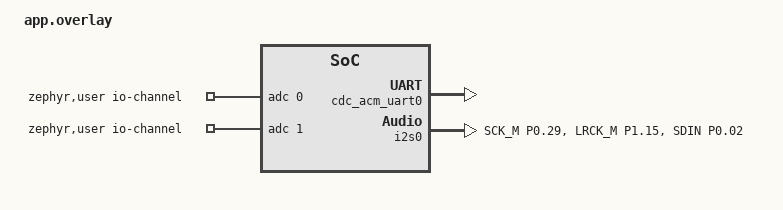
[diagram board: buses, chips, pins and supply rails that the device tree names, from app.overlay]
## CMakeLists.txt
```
# SPDX-License-Identifier: Apache-2.0

cmake_minimum_required(VERSION 3.20.0)
set(QEMU_EXTRA_FLAGS -s)
set(CMAKE_EXPORT_COMPILE_COMMANDS ON)
find_package(Zephyr REQUIRED HINTS $ENV{ZEPHYR_BASE})
project(console)
set(CMAKE_EXPORT_COMPILE_COMMANDS ON)
set(CMAKE_COLOR_DIAGNOSTICS ON)
set(CMAKE_C_FLAGS "${CMAKE_C_FLAGS} -Wall -Wextra -Wformat -Wformat-security -Wshadow -Wwrite-strings -Wcast-qual -Wswitch-default -Wswitch-enum -Wconversion -Wunreachable-code -Wstrict-prototypes")

target_sources(app PRIVATE 
    src/main.c
    src/provision.c
    src/uart.c
    src/board.c
    src/heartbeat.c
    src/msgdata.c
    src/microphone.c
    src/datastructures.c)

target_include_directories(app PRIVATE ${CMAKE_CURRENT_SOURCE_DIR}/includes)
```

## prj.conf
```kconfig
CONFIG_USB_DEVICE_STACK=y
CONFIG_USB_DEVICE_PRODUCT="Mesh DK 1 USB"

CONFIG_SERIAL=y
CONFIG_CONSOLE=y
CONFIG_UART_CONSOLE=n
CONFIG_UART_LINE_CTRL=y
#CONFIG_DK_LIBRARY=y

CONFIG_POSIX_API=y

# Bluetooth configuration
CONFIG_BT=y
CONFIG_BT_COMPANY_ID=0x0059
CONFIG_BT_DEVICE_NAME="Mesh DK 1"
CONFIG_BT_L2CAP_TX_BUF_COUNT=32
CONFIG_BT_OBSERVER=y
CONFIG_BT_PERIPHERAL=y
CONFIG_BT_SETTINGS=y

CONFIG_BT_CTLR_PHY_CODED=y


# Long range configuration
CONFIG_BT_CTLR_ADV_EXT=y
CONFIG_BT_CTLR_ADV_PERIODIC=y
CONFIG_BT_CTLR_TX_PWR_PLUS_8=y # 8 dBm
CONFIG_BT_EXT_ADV=y


CONFIG_SYSTEM_WORKQUEUE_STACK_SIZE=2048
#CONFIG_INIT_STACKS=y
#CONFIG_MAIN_STACK_SIZE=1408
#CONFIG_SYSTEM_WORKQUEUE_STACK_SIZE=2048
# The Bluetooth API should not be used from a preemptive thread:
CONFIG_MAIN_THREAD_PRIORITY=-2

CONFIG_BT=y
CONFIG_BT_TINYCRYPT_ECC=y
#CONFIG_BT_DEBUG_LOG=y
CONFIG_BT_OBSERVER=y
CONFIG_BT_BROADCASTER=y

CONFIG_BT_MESH=y
CONFIG_BT_MESH_SUBNET_COUNT=1
CONFIG_BT_MESH_APP_KEY_COUNT=1
CONFIG_BT_MESH_ADV_BUF_COUNT=10
CONFIG_BT_MESH_TX_SEG_MSG_COUNT=3
CONFIG_BT_MESH_MODEL_GROUP_COUNT=2
CONFIG_BT_MESH_LABEL_COUNT=0
CONFIG_BT_MESH_CFG_CLI=y
CONFIG_BT_MESH_HEALTH_CLI=y
CONFIG_BT_MESH_BEACON_ENABLED=n
CONFIG_BT_MESH_RELAY=y
CONFIG_BT_MESH_RELAY_RETRANSMIT_COUNT=3

# ensure that we have 12 * 32 byte message length :^)
CONFIG_BT_MESH_RX_SEG_MAX=32
CONFIG_BT_MESH_TX_SEG_MAX=32

CONFIG_BT_MESH_PROVISIONER=y
CONFIG_BT_MESH_PROV_DEVICE=y
CONFIG_BT_MESH_CDB=y
CONFIG_BT_MESH_CDB_NODE_COUNT=16
CONFIG_BT_MESH_CDB_SUBNET_COUNT=3
CONFIG_BT_MESH_CDB_APP_KEY_COUNT=3

CONFIG_BT_SETTINGS=n # cache
CONFIG_FLASH=y
CONFIG_FLASH_PAGE_LAYOUT=y
CONFIG_FLASH_MAP=y
CONFIG_NVS=y
CONFIG_SETTINGS=n
CONFIG_BT_MESH_RPL_STORE_TIMEOUT=600

#CONFIG_BT_MESH_DEBUG=y
#CONFIG_BT_MESH_DEBUG_SETTINGS=y
#CONFIG_BT_MESH_DEBUG_NET=y
#CONFIG_BT_MESH_DEBUG_MODEL=y
#CONFIG_BT_MESH_DEBUG_TRANS=y
#CONFIG_BT_MESH_DEBUG_ACCESS=y

#CONFIG_BT_MESH_LOW_POWER=y
#CONFIG_BT_MESH_DEBUG_PROV=y
#CONFIG_BT_MESH_DEBUG_LOW_POWER=y
#CONFIG_BT_MESH_DEBUG_BEACON=y
#CONFIG_BT_MESH_DEBUG_CRYPTO=y
#CONFIG_BT_MESH_DEBUG_ADV=y

# I2S Configuration
CONFIG_I2S=y
```

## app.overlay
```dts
/*
 * Copyright (c) 2021 Nordic Semiconductor ASA
 *
 * SPDX-License-Identifier: Apache-2.0
 */

/ {
	chosen {
		zephyr,console = &cdc_acm_uart0;
	};
};

&zephyr_udc0 {
	cdc_acm_uart0: cdc_acm_uart0 {
		compatible = "zephyr,cdc-acm-uart";
	};
};

/ {
	zephyr,user {
		io-channels = <&adc 0>, <&adc 1>;
	};

};

&pinctrl {
	i2s0_default_alt: i2s0_default_alt {
		group1 {
			psels = <NRF_PSEL(I2S_SCK_M, 0, 29)>,
			        <NRF_PSEL(I2S_LRCK_M, 1, 15)>,
			        <NRF_PSEL(I2S_SDIN, 0, 02)>;
		};
	};
};

i2s_rx: &i2s0 {
	status = "okay";
	pinctrl-0 = <&i2s0_default_alt>;
	pinctrl-names = "default";
};
```

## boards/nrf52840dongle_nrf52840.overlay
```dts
/* SPDX-License-Identifier: LicenseRef-Nordic-5-Clause */

&uart1 {
	compatible = "nordic,nrf-uarte";
	current-speed = <115200>;
	status = "okay";
	pinctrl-0 = <&uart1_default>;
	pinctrl-1 = <&uart1_sleep>;
	pinctrl-names = "default", "sleep";
  };

&uart0 {
	disable-rx;
};

&gpiote {
	interrupts = <6 NRF_DEFAULT_IRQ_PRIORITY>;
};

&pinctrl {
	uart1_default: uart1_default {
	   group1 {
		  psels = <NRF_PSEL(UART_TX, 0, 13)>,
				  <NRF_PSEL(UART_RX, 0, 15)>;
	   };
	};
	/* required if CONFIG_PM_DEVICE=y */
	uart1_sleep: uart1_sleep {
	   group1 {
		  psels = <NRF_PSEL(UART_TX, 0, 13)>,
				  <NRF_PSEL(UART_RX, 0, 15)>;
		  low-power-enable;
	   };
	};
};
```

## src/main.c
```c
/*
 * Copyright (c) 2016 Intel Corporation.
 *
 * SPDX-License-Identifier: Apache-2.0
 */

#include <bluetooth/mesh/models.h>
#include <dk_buttons_and_leds.h>
#include <zephyr/bluetooth/bluetooth.h>
#include <zephyr/bluetooth/mesh/main.h>
#include <zephyr/drivers/uart.h>
#include <zephyr/usb/usb_device.h>
#include <zephyr/zephyr.h>

#include "board.h"
#include "heartbeat.h"
#include "microphone.h"
#include "msgdata.h"
#include "provision.h"

BUILD_ASSERT(DT_NODE_HAS_COMPAT(DT_CHOSEN(zephyr_console), zephyr_cdc_acm_uart),
    "Console device is not ACM CDC UART device");

void main(void) {
    /* uart */
    uart_init(dev);
    dev_uuid_init();

    start_i2s_sampling();

    // printk("Startup \r\n");

    // printk("Press button 1 within 5 seconds to make this node a provisioner\r\n");
    // if (wait_for_button_press(5)) {
    //     provision();
    //     printk("Done provisioning\r\n");
    // } else {
    //     msgdata_init();
    //     // Heartbeat init AFTER msgdata init
    //     heartbeat_init(5);
    // }

    // printk("Main reached end :)\r\n");

    // // Mic stuff
    // // while (1) {
    // //     k_sleep(K_SECONDS(1));
    // //     if (bt_mesh_is_provisioned()) {
    // //         printk("Node is provisioned!\r\n");
    // //         printk("Mic Init \r\n");
    // //         microphone_init();
    // //         break;
    // //     }
    // // }
    // // printk("Ready to do work!\r\n");
    // // while (1) {
    // //     k_sleep(K_SECONDS(1));
    // // }

    printk("done\n");
    while (1) {
        k_sleep(K_SECONDS(1));
    }
}
```

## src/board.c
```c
/* board.c - Generic HW interaction hooks */

/*
 * Copyright (c) 2021 Nordic Semiconductor
 *
 * SPDX-License-Identifier: Apache-2.0
 */

#include "board.h"
#include <zephyr/bluetooth/mesh.h>
#include <zephyr/drivers/gpio.h>

/* Locate led0 as alias or label by that name */
#if DT_NODE_EXISTS(DT_ALIAS(led0))
#define LED0 DT_ALIAS(led0)
#elif DT_NODE_EXISTS(DT_NODELABEL(led0))
#define LED0 DT_NODELABEL(led0)
#else
#define LED0 DT_INVALID_NODE
#endif

/* Locate button0 as alias or label by sw0 or button0 */
#if DT_NODE_EXISTS(DT_ALIAS(sw0))
#define BUTTON0 DT_ALIAS(sw0)
#elif DT_NODE_EXISTS(DT_ALIAS(button0))
#define BUTTON0 DT_ALIAS(button0)
#elif DT_NODE_EXISTS(DT_NODELABEL(sw0))
#define BUTTON0 DT_NODELABEL(sw0)
#elif DT_NODE_EXISTS(DT_NODELABEL(button0))
#define BUTTON0 DT_NODELABEL(button0)
#else
#define BUTTON0 DT_INVALID_NODE
#endif

#if DT_NODE_EXISTS(LED0)
#define LED0_DEV DT_PHANDLE(LED0, gpios)
#define LED0_PIN DT_PHA(LED0, gpios, pin)
#define LED0_FLAGS DT_PHA(LED0, gpios, flags)

static const struct device* const led_dev = DEVICE_DT_GET(LED0_DEV);
#endif /* LED0 */

#if DT_NODE_EXISTS(BUTTON0)
#define BUTTON0_DEV DT_PHANDLE(BUTTON0, gpios)
#define BUTTON0_PIN DT_PHA(BUTTON0, gpios, pin)
#define BUTTON0_FLAGS DT_PHA(BUTTON0, gpios, flags)

static const struct device* const button_dev = DEVICE_DT_GET(BUTTON0_DEV);
static struct k_work* button_work;

static void button_cb(const struct device* port, struct gpio_callback* cb,
    gpio_port_pins_t pins) {
    k_work_submit(button_work);
}
#endif /* BUTTON0 */

static int led0_init(void) {
#if DT_NODE_EXISTS(LED0)
    int err;

    if (!device_is_ready(led_dev)) {
        return -ENODEV;
    }

    err = gpio_pin_configure(led_dev, LED0_PIN,
        LED0_FLAGS | GPIO_OUTPUT_INACTIVE);
    if (err) {
        return err;
    }
#else
    printk("WARNING: LEDs not supported on this board.\n");
#endif

    return 0;
}

// intializes button 0 to trigger an interrupt on the rising edge
static int button0_init(struct k_work* button_pressed) {
#if DT_NODE_EXISTS(BUTTON0)
    int err;

    err = gpio_pin_configure(button_dev, BUTTON0_PIN,
        BUTTON0_FLAGS | GPIO_INPUT);
    if (err) {
        return err;
    }

    static struct gpio_callback gpio_cb;

    err = gpio_pin_interrupt_configure(button_dev, BUTTON0_PIN,
        GPIO_INT_EDGE_TO_ACTIVE);
    if (err) {
        return err;
    }

    button_work = button_pressed;

    gpio_init_callback(&gpio_cb, button_cb, BIT(BUTTON0_PIN));
    gpio_add_callback(button_dev, &gpio_cb);
#else
    #error "Buttons not supported on this board!"
#endif
    return 0;
}

int board_init(struct k_work* button_pressed) {
    int err;

    err = led0_init();
    if (err) {
        printk("Failed to init LEDs: %d\n", err);
        return err;
    }

    return button0_init(button_pressed);
}

void board_led0_set(bool val) {
#if DT_NODE_EXISTS(LED0)
    gpio_pin_set(led_dev, LED0_PIN, val);
#else
    printk("LEDs are not supported on this board, failed to set led0 via board_led0_set.\n");
#endif
}
```

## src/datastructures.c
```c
#include "datastructures.h"

#include "custom_assert.h"
#include "printk.h"
#include <stdint.h>
#include <string.h>

bool samples_deserialize(const uint8_t* buf, size_t size, struct Samples* out_samples) {
    if (size < SAMPLES_SERIALIZE_BUFFER_SIZE) {
        printk("samples_deserialize: buffer too small to hold samples\r\n");
        return false;
    }
    assert_not_null(buf);
    assert_not_null(out_samples);
    memcpy(out_samples, buf, sizeof(struct Samples));
    return true;
}

bool samples_serialize(uint8_t* buf, size_t size, const struct Samples* out_samples) {
    if (size < SAMPLES_SERIALIZE_BUFFER_SIZE) {
        printk("samples_serialize: buffer too small to hold samples\r\n");
        return false;
    }
    assert_not_null(buf);
    assert_not_null(out_samples);
    memcpy(buf, out_samples, sizeof(struct Samples));
    return true;
}
```

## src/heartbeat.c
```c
#include <stdio.h>
#include <stdlib.h>
#include <string.h>

#include "heartbeat.h"
#include "msgdata.h"

#include "printk.h"

static uint8_t dev_uuid[16];
static size_t dev_uuid_size = 0;

static struct k_timer timer;
static void timer_callback(struct k_timer* timer) {
    char buf[dev_uuid_size * 2 + 1];
    // Add uuid to msg
    char* iter = buf;
    for (size_t i = 0; i < dev_uuid_size; ++i) {
        sprintf(iter, "%02x", dev_uuid[i]);
        iter += 2;
    }
    buf[sizeof(buf) - 1] = 0;
    if (bt_mesh_is_provisioned()) {
        (void)gen_msg_send(MSG_HEARTBEAT, buf, sizeof(buf));
        return;
    }
}

void heartbeat_init(uint8_t sleeptime) {
    if (IS_ENABLED(CONFIG_HWINFO)) {
        int size = hwinfo_get_device_id(dev_uuid, sizeof(dev_uuid));
        if (size < 0) {
            dev_uuid[0] = 0xdd;
            dev_uuid[1] = 0xdd;
            dev_uuid_size = 2;
        } else {
            dev_uuid_size = size;
        }
    }
    k_timer_init(&timer, timer_callback, NULL);
    k_timer_start(&timer, K_SECONDS(sleeptime), K_SECONDS(sleeptime));
}
```

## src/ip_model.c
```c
#include "ip_model.h"

#include "custom_assert.h"
#include "printk.h"
#include "provision.h"
#include <string.h>

bool samples_deserialize(const uint8_t* buf, size_t size, struct Samples* out_samples) {
    if (size < SAMPLES_SERIALIZE_BUFFER_SIZE) {
        printk("samples_deserialize: buffer too small to hold samples\r\n");
        return false;
    }
    assert_not_null(buf);
    assert_not_null(out_samples);
    memcpy(out_samples, buf, sizeof(struct Samples));
    return true;
}

bool samples_serialize(uint8_t* buf, size_t size, const struct Samples* out_samples) {
    if (size < SAMPLES_SERIALIZE_BUFFER_SIZE) {
        printk("samples_serialize: buffer too small to hold samples\r\n");
        return false;
    }
    assert_not_null(buf);
    assert_not_null(out_samples);
    memcpy(buf, out_samples, sizeof(struct Samples));
    return true;
}

// Simple ring-buffer implementation of a queue.
static struct Samples samples_send_q[SAMPLES_TO_SEND_QUEUE_LEN];
// must be locked before every access
K_MUTEX_DEFINE(samples_send_q_mtx);
// read&write pointers
static size_t samples_send_q_rp = 0;
static size_t samples_send_q_wp = 0;

bool enqueue_samples_to_send(const struct Samples* samples) {
    bool result = true;
    k_mutex_lock(&samples_send_q_mtx, K_FOREVER);

    assert_not_null(samples);

    {
        if ((samples_send_q_wp + 1) % sizeof(samples_send_q) == samples_send_q_rp) {
            printk("Error: Samples queue is full\r\n");
            result = false;
            goto end;
        }
        printk("Enqueueing samples, wp=%u, rp=%u\r\n", samples_send_q_wp, samples_send_q_rp);
        memcpy(&samples_send_q[samples_send_q_wp], samples, sizeof(struct Samples));
        samples_send_q_wp = (samples_send_q_wp + 1) % sizeof(samples_send_q);
        printk("Enqueued samples, wp=%u, rp=%u\r\n", samples_send_q_wp, samples_send_q_rp);
    }

end:
    k_mutex_unlock(&samples_send_q_mtx);
    return result;
}

bool dequeue_samples_to_send(struct Samples* out_samples) {
    bool result = true;
    k_mutex_lock(&samples_send_q_mtx, K_FOREVER);

    assert_not_null(out_samples);

    {
        if (samples_send_q_rp == samples_send_q_wp) {
            printk("Error: Samples queue is empty\r\n");
            result = false;
            goto end;
        }
        printk("Dequeueing samples, wp=%u, rp=%u\r\n", samples_send_q_wp, samples_send_q_rp);
        memcpy(out_samples, &samples_send_q[samples_send_q_rp], sizeof(struct Samples));
        samples_send_q_rp = (samples_send_q_rp + 1) % sizeof(samples_send_q);
        printk("Dequeued samples, wp=%u, rp=%u\r\n", samples_send_q_wp, samples_send_q_rp);
    }

end:
    k_mutex_unlock(&samples_send_q_mtx);
    return result;
}

static void send_start(uint16_t duration, int err, void* cb_data) {
    printk("send start, duration=%d, err=%d, addr=%d\r\n", duration, err, (uint16_t)cb_data);
}

static void send_end(int err, void* cb_data) {
    printk("send end, err=%d, addr=%d\r\n", err, (uint16_t)cb_data);
}

static struct bt_mesh_send_cb send_cb = {
    .start = send_start,
    .end = send_end,
};

int handle_message_micdata(struct bt_mesh_model* model, struct bt_mesh_msg_ctx* ctx, struct net_buf_simple* buf) {
    // Message handler code
    printk("Got MICDATA message\r\n");
    return 0;
}

int send_message(struct bt_mesh_model* model, uint16_t addr) {
    struct bt_mesh_msg_ctx ctx = {
        .net_idx = 0,
        .addr = addr,
        .app_idx = model->keys[0],
        .send_ttl = BT_MESH_TTL_DEFAULT,
        .send_rel = true,
    };

    BT_MESH_MODEL_BUF_DEFINE(buf, MESSAGE_MICDATA_OPCODE, MESSAGE_MICDATA_LEN);
    bt_mesh_model_msg_init(&buf, MESSAGE_MICDATA_OPCODE);

    printk("Sending MICDATA message to 0x%04x\r\n", addr);

    const char mem[] = "hello";

    net_buf_simple_add_mem(&buf, mem, sizeof(mem));

    return bt_mesh_model_send(model, &ctx, &buf, &send_cb, (void*)addr);
}

bool send_micdata_from_queue(uint16_t addr) {
    struct Samples samples;
    if (!dequeue_samples_to_send(&samples)) {
        return false;
    }

    struct bt_mesh_model* model = get_msg_model();
    if (!model) {
        printk("Error: Message model is NULL\r\n");
        return false;
    }

    // TODO: do for all addresses, not just one.
    struct bt_mesh_msg_ctx ctx = {
        .addr = addr,
        .app_idx = model->keys[0],
        .send_ttl = BT_MESH_TTL_DEFAULT,
        .send_rel = true,
    };

    BT_MESH_MODEL_BUF_DEFINE(buf, MESSAGE_MICDATA_OPCODE, MESSAGE_MICDATA_LEN);
    bt_mesh_model_msg_init(&buf, MESSAGE_MICDATA_OPCODE);

    // serialize samples into message buffer
    if (!samples_serialize(buf.data, MESSAGE_MICDATA_LEN, &samples)) {
        return false;
    }
    buf.len = SAMPLES_SERIALIZE_BUFFER_SIZE;

    // TODO: model is undefined
    // printk("Sending MICDATA message to 0x%04x with app_idx 0x%04x\r\n", addr, model->keys[0]);
    // return bt_mesh_model_send(model, &ctx, &buf, &send_cb, (void*)addr);
    return false;
}
```

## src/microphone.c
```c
#include "microphone.h"
#include "printk.h"

#include <zephyr/drivers/i2s.h>

#define I2S_RX_NODE DT_NODELABEL(i2s_rx)

#define SAMPLE_FREQUENCY 32000
#define SAMPLE_BIT_WIDTH 24
#define BYTES_PER_SAMPLE sizeof(int32_t)
#define SAMPLES_PER_CH_PER_FRAME 128
#define NUMBER_OF_CHANNELS 2
#define SAMPLES_PER_FRAME (SAMPLES_PER_CH_PER_FRAME * NUMBER_OF_CHANNELS)
#define BYTES_PER_FRAME (SAMPLES_PER_FRAME * BYTES_PER_SAMPLE)
#define TIMEOUT 1000

K_MEM_SLAB_DEFINE_STATIC(mem_slab, BYTES_PER_FRAME, 2, 4);

static bool configure_stream(const struct device* i2s_dev_rx, const struct i2s_config* config) {
    int ret;

    ret = i2s_configure(i2s_dev_rx, I2S_DIR_RX, config);

    if (ret < 0) {
        printk("Failed to configure RX stream: %d\n", ret);
        return false;
    }

    return true;
}

static bool trigger_command(const struct device* i2s_dev_rx, enum i2s_trigger_cmd cmd) {
    int ret;

    ret = i2s_trigger(i2s_dev_rx, I2S_DIR_RX, cmd);
    if (ret < 0) {
        printk("Failed to trigger command %d on RX: %d\n", cmd, ret);
        return false;
    }

    return true;
}

static void process_block_data(void* mem_block, uint32_t number_of_samples) {
    printk("a\n");
    k_mem_slab_free(&mem_slab, &mem_block);
    return;
}

void start_i2s_sampling(void) {
    const struct device* const i2s_dev_rx = DEVICE_DT_GET(I2S_RX_NODE);
    struct i2s_config config;

    if (!device_is_ready(i2s_dev_rx)) {
        printk("I2S device is not ready\n", i2s_dev_rx->name);
        return;
    }

    config.word_size = SAMPLE_BIT_WIDTH;
    config.channels = NUMBER_OF_CHANNELS;
    config.format = I2S_FMT_DATA_FORMAT_I2S;
    config.options = I2S_OPT_BIT_CLK_MASTER | I2S_OPT_FRAME_CLK_MASTER;
    config.frame_clk_freq = SAMPLE_FREQUENCY;
    config.mem_slab = &mem_slab;
    config.block_size = BYTES_PER_FRAME;
    config.timeout = TIMEOUT;

    if (!configure_stream(i2s_dev_rx, &config)) {
        return;
    }

    for (;;) {
        if (!trigger_command(i2s_dev_rx, I2S_TRIGGER_START)) {
            return;
        }

        while (1) {
            void* mem_block;
            uint32_t block_size;
            int ret;

            ret = i2s_read(i2s_dev_rx, &mem_block, &block_size);
            if (ret < 0) {
                printk("Failed to read data: %d\n", ret);
                break;
            }

            process_block_data(&mem_block, SAMPLES_PER_FRAME);
        }

        // if (!trigger_command(i2s_dev_rx, I2S_TRIGGER_STOP)) {
        //     return;
        // }
    }
}
```

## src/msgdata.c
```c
#include "msgdata.h"
#include "datastructures.h"
#include "uart.h"
#include <errno.h>
#include <stdint.h>
#include <stdio.h>
#include <zephyr/net/buf.h>

#define OP_ONOFF_GET BT_MESH_MODEL_OP_2(0x82, 0x01)
#define OP_ONOFF_SET BT_MESH_MODEL_OP_2(0x82, 0x02)
#define OP_ONOFF_SET_UNACK BT_MESH_MODEL_OP_2(0x82, 0x03)
#define OP_ONOFF_STATUS BT_MESH_MODEL_OP_2(0x82, 0x04)

static struct device* uart_dev;
static char* uart_buffer[5]; // Create buffer for uart read
uint16_t primary_addr = 0; // This node's address
unsigned int recv_addr = BT_MESH_ADDR_ALL_NODES;
static struct k_sem prov_sem;
static struct bt_mesh_model models[];
static bool configured = false;

static uint32_t uptime;
#define MICDATA_STR_LEN 2048
static char* micdata_str[MICDATA_STR_LEN];
#define FIFO_BUF_LEN 128
static uint8_t clean_data[FIFO_BUF_LEN];
static int rx_len = 0;
static uint8_t dev_uuid[16];

// Node added cb (provisioning complete and configured)
static void prov_node_added(uint16_t net_idx, uint8_t uuid[16], uint16_t addr, uint8_t num_elem) {
    printk("Device 0x%04x provisioned", addr);
    k_sem_give(&prov_sem);
}
#define OP_GENERIC_MSG BT_MESH_MODEL_OP_2(0x82, 0x03)
#define OP_ONOFF_STATUS BT_MESH_MODEL_OP_2(0x82, 0x04)

static void health_srv_attention_on(struct bt_mesh_model* mod) {
    board_led0_set(true);
}

static void health_srv_attention_off(struct bt_mesh_model* mod) {
    board_led0_set(false);
}

static const struct bt_mesh_health_srv_cb health_cb = {
    .attn_on = health_srv_attention_on,
    .attn_off = health_srv_attention_off,
};

static struct bt_mesh_health_srv health_srv = {
    .cb = &health_cb,
};

BT_MESH_HEALTH_PUB_DEFINE(health_pub, 0);

static struct {
    char* val;
    uint16_t len;
    uint8_t tid;
    uint16_t src;
    uint32_t transition_time;
    struct k_work_delayable work;
} msg;

/* OnOff messages' transition time and remaining time fields are encoded as an
 * 8 bit value with a 6 bit step field and a 2 bit resolution field.
 * The resolution field maps to:
 * 0: 100 ms
 * 1: 1 s
 * 2: 10 s
 * 3: 20 min
 */
static const uint32_t time_res[] = {
    100,
    MSEC_PER_SEC,
    10 * MSEC_PER_SEC,
    10 * 60 * MSEC_PER_SEC,
};

static inline int32_t model_time_decode(uint8_t val) {
    uint8_t resolution = (val >> 6) & BIT_MASK(2);
    uint8_t steps = val & BIT_MASK(6);

    if (steps == 0x3f) {
        return SYS_FOREVER_MS;
    }

    return steps * time_res[resolution];
}

static bool received = false;
static void msg_timeout(struct k_work* work) {
    if (msg.transition_time) {
        /* Start transition.
         *
         * The LED should be on as long as the transition is in
         * progress, regardless of the target value, according to the
         * Bluetooth Mesh Model specification, section 3.1.1.
         */
        board_led0_set(true);

        k_work_reschedule(&msg.work, K_MSEC(msg.transition_time));
        msg.transition_time = 0;
        return;
    }

    board_led0_set(!received);
}

/* Generic OnOff Server message handlers */

static int gen_msg_get(struct bt_mesh_model* model,
    struct bt_mesh_msg_ctx* ctx,
    struct net_buf_simple* buf) {
    // msg_status_send(model, ctx);
    return 0;
}

// Receiving the message and handling it
static int gen_msg_generic(struct bt_mesh_model* model,
    struct bt_mesh_msg_ctx* ctx,
    struct net_buf_simple* buf) {

    enum msg_type type = net_buf_simple_pull_u8(buf);
    uint16_t len = net_buf_simple_pull_le16(buf);
    uint8_t* msg_buf = net_buf_simple_pull_mem(buf, len);

    switch (type) {
    case MSG_HELLO:
        printk("bt: got hello message: '%s'\n", msg_buf);
        break;
    case MSG_HEARTBEAT:
        printk("bt: got heartbeat message: '%s'\n", msg_buf);
        break;
    case MSG_SND_COMM:
        printk("bt: got SND message: '%s'\n", msg_buf);
        break;
    case MSG_UPTIME:
        printk("bt: got uptime cmd: '%s'\n", msg_buf);
        // Send uptime to the gateway
        uptime = k_uptime_get_32();
        char buf_addr[sizeof(dev_uuid) + 1];
        char* iter = buf_addr;
        for (size_t i = 0; i < 16; ++i) {
            sprintf(iter, "%02x", dev_uuid[i]);
            iter += 2;
        }
        buf_addr[sizeof(buf_addr) - 1] = 0;
        int len = sprintf(&clean_data[0], "%d, %s", uptime, buf_addr);
        gen_msg_send(MSG_UPTIME_ACK, &clean_data[0], (size_t)len + 1);
        break;
    case MSG_UPTIME_ACK:
        printk("bt: got uptime data: '%s'\n", msg_buf);
        break;
    case MSG_MIC_DATA:
        // don't print, because it's binary! :)
        printk("bt: got MIC message (binary)\n");
        struct Samples samples;
        if (!samples_deserialize(msg_buf, (size_t)len, &samples)) {
            printk("Failed to deserialize samples from MSG_MIC_DATA!\n");
        } else {
            printk("bt: MIC message contains %u samples\n", samples.n_samples);
            memset(micdata_str, 0, MICDATA_STR_LEN);
            char* ptr = micdata_str;
            ptr += sprintf(ptr, "micdata:");
            for (size_t i = 0; i < samples.n_samples; ++i) {
                ptr += sprintf(ptr, "%d,%d,%lld,",
                    samples.samples[i].channels[0],
                    samples.samples[i].channels[1],
                    samples.samples[i].time);
                if (ptr > micdata_str + MICDATA_STR_LEN) {
                    // If you get this, try increasing the MICDATA_STR_LEN, or send twice (in chunks)
                    printk("Ran out of memory for micdata!\n");
                    return -ENOMEM;
                }
            }
            // Write the data to the uart
            uart_write_str(dev, (const char*)micdata_str);
            // make sure it looks pretty
            uart_write_str(dev, "\n");
        }
        break;
    case MSG_ADV_COMM:
        printk("bt: got ADV message: '%s'\n", msg_buf);
        int adv_addr = atoi(msg_buf);
        printk("ADV command received %d %s\n", adv_addr, msg_buf);
        // Compare msg_buf with the address of the device
        if (primary_addr != adv_addr) {
            printk("Setup gateway ID: %s\n", msg_buf);
            recv_addr = (unsigned int)adv_addr;
        }
        break;
    default:
        printk("Error: Unhandled bt message type '%c' (%d)\n", type, type);
        return -1;
    }

    return 0;
}

static int gen_msg_set(struct bt_mesh_model* model,
    struct bt_mesh_msg_ctx* ctx,
    struct net_buf_simple* buf) {
    printk("gen_msg_set\n");
    (void)gen_msg_generic(model, ctx, buf);
    // msg_status_send(model, ctx);

    return 0;
}

static const struct bt_mesh_model_op gen_msg_srv_op[] = {
    { OP_ONOFF_GET, BT_MESH_LEN_EXACT(0), gen_msg_get },
    { OP_ONOFF_SET, BT_MESH_LEN_MIN(2), gen_msg_set },
    { OP_GENERIC_MSG, BT_MESH_LEN_MIN(2), gen_msg_generic },
    BT_MESH_MODEL_OP_END,
};

/* Generic OnOff Client */

static int gen_msg_status(struct bt_mesh_model* model,
    struct bt_mesh_msg_ctx* ctx,
    struct net_buf_simple* buf) {
    uint8_t present = net_buf_simple_pull_u8(buf);

    if (buf->len) {
        uint8_t target = net_buf_simple_pull_u8(buf);
        int32_t remaining_time = model_time_decode(net_buf_simple_pull_u8(buf));

        printk("OnOff status: %c -> %c: (%d ms)\n", present,
            target, remaining_time);
        return 0;
    }

    printk("OnOff status: %c\n", present);

    return 0;
}

static const struct bt_mesh_model_op gen_msg_cli_op[] = {
    { OP_ONOFF_STATUS, BT_MESH_LEN_MIN(1), gen_msg_status },
    BT_MESH_MODEL_OP_END,
};

/* This application only needs one element to contain its models */
static struct bt_mesh_model models[] = {
    BT_MESH_MODEL_CFG_SRV,
    BT_MESH_MODEL_HEALTH_SRV(&health_srv, &health_pub),
    BT_MESH_MODEL(BT_MESH_MODEL_ID_GEN_ONOFF_SRV, gen_msg_srv_op, NULL,
        NULL),
    BT_MESH_MODEL(BT_MESH_MODEL_ID_GEN_ONOFF_CLI, gen_msg_cli_op, NULL,
        NULL),
};

static struct bt_mesh_elem elements[] = {
    BT_MESH_ELEM(0, models, BT_MESH_MODEL_NONE),
};

static const struct bt_mesh_comp comp = {
    .cid = BT_COMP_ID_LF,
    .elem = elements,
    .elem_count = ARRAY_SIZE(elements),
};

/* Provisioning */
static int output_number(bt_mesh_output_action_t action, uint32_t number) {
    printk("OOB Number: %u\n", number);

    k_sem_give(&prov_sem);

    return 0;
}

// Provisioning is complete but NOT configured yet
static void prov_complete(uint16_t net_idx, uint16_t addr) {
    // This function will be called when a BT mesh is provisioned
    // Do something here, such as printing a message or setting a flag
    printk("Provisioning complete: net_idx = %u, addr = %u\n", net_idx, addr);

    primary_addr = addr;
    k_sem_give(&prov_sem);

    // send_msg_from_uart(dev);

    // // Send a message to all nodes
    // gen_msg_send("Hello from the primary node!");
}

static void prov_reset(void) {
    bt_mesh_prov_enable(BT_MESH_PROV_ADV | BT_MESH_PROV_GATT);
    k_sem_give(&prov_sem);
}

static const struct bt_mesh_prov prov = {
    .uuid = dev_uuid,
    .output_size = 4,
    .output_actions = BT_MESH_DISPLAY_NUMBER,
    .output_number = output_number,
    .complete = prov_complete,
    .reset = prov_reset,
    .node_added = prov_node_added,
};

// Send a message Generic Client to all nodes.
int gen_msg_send(enum msg_type type, const void* msg_buf, size_t len) {
    // printk("gen_msg_send to addr: %d\n", recv_addr);
    struct bt_mesh_msg_ctx ctx = {
        .app_idx = models[3].keys[0], /* Use the bound key */
        .addr = recv_addr,
        .send_ttl = BT_MESH_TTL_DEFAULT,
    };
    static uint8_t tid;

    if (ctx.app_idx == BT_MESH_KEY_UNUSED) {
        printk("The Generic OnOff Client must be bound to a key before "
               "sending.\n");
        return -ENOENT;
    }

    const size_t max = UINT16_MAX - sizeof(uint16_t) - sizeof(uint8_t);
    if (len > max) {
        printk("Error: Tried to send message of length %d, but maximum possible is %d", len, max);
        return -1;
    }

    // size is:
    // 1 byte header
    // 2 bytes length
    // <length> bytes data
    BT_MESH_MODEL_BUF_DEFINE(buf, OP_GENERIC_MSG, (uint16_t)(sizeof(uint8_t) + sizeof(uint16_t) + len));
    bt_mesh_model_msg_init(&buf, OP_GENERIC_MSG);

    net_buf_simple_add_u8(&buf, (uint8_t)type);
    net_buf_simple_add_le16(&buf, (uint16_t)len);
    net_buf_simple_add_mem(&buf, (const void*)msg_buf, len);

    printk("Sending message of length %d\n", len);

    int err = bt_mesh_model_send(&models[3], &ctx, &buf, NULL, NULL);
    if (err) {
        printk("Error: bt_mesh_model_send failed: err=%d\n", err);
    }
    return err;
}

int mic_msg_send(const struct Samples* samples) {
    uint8_t buf[SAMPLES_SERIALIZE_BUFFER_SIZE];
    if (!samples_serialize(buf, sizeof(buf), samples)) {
        printk("Failed to serialize samples!\n");
        return -1;
    }
    return gen_msg_send(MSG_MIC_DATA, buf, sizeof(buf));
}

static void button_pressed(struct k_work* work) {
    if (bt_mesh_is_provisioned()) {
        const char hello_msg[] = "hello world";
        (void)gen_msg_send(MSG_HELLO, hello_msg, sizeof(hello_msg));
        return;
    }

    /* Self-provision with an arbitrary address.
     *
     * NOTE: This should never be done in a production environment.
     *       Addresses should be assigned by a provisioner, and keys should
     *       be generated from true random numbers. It is done in this
     *       sample to allow testing without a provisioner.
     */
    static uint8_t net_key[16];
    static uint8_t dev_key[16];
    static uint8_t app_key[16];
    uint16_t addr;
    int err;

    if (IS_ENABLED(CONFIG_HWINFO)) {
        addr = sys_get_le16(&dev_uuid[0]) & BIT_MASK(15);
    } else {
        addr = k_uptime_get_32() & BIT_MASK(15);
    }

    printk("Self-provisioning with address 0x%04x\n", addr);
    err = bt_mesh_provision(net_key, 0, 0, 0, addr, dev_key);
    if (err) {
        printk("Provisioning failed (err: %d)\n", err);
        return;
    }

    /* Add an application key to both Generic OnOff models: */
    err = bt_mesh_app_key_add(0, 0, app_key);
    if (err) {
        printk("App key add failed (err: %d)\n", err);
        return;
    }

    /* Models must be bound to an app key to send and receive messages with
     * it:
     */
    models[2].keys[0] = 0;
    models[3].keys[0] = 0;

    printk("Provisioned and configured!\n");
}

static void bt_ready(int err) {
    if (err) {
        printk("Bluetooth init failed (err %d)\n", err);
        return;
    }

    printk("Bluetooth initialized\n");

    k_sem_init(&prov_sem, 0, 1);
    err = bt_mesh_init(&prov, &comp);
    if (err) {
        printk("Initializing mesh failed (err %d)\n", err);
        return;
    }

    if (IS_ENABLED(CONFIG_SETTINGS)) {
        settings_load();
    }

    /* This will be a no-op if settings_load() loaded provisioning info */
    bt_mesh_prov_enable(BT_MESH_PROV_ADV | BT_MESH_PROV_GATT);

    printk("Mesh initialized\n");
}

void msgdata_init(void) {
    uart_dev = dev;
    static struct k_work button_work;
    int err = -1;

    printk("Msg data initializing...\n");

    if (IS_ENABLED(CONFIG_HWINFO)) {
        err = hwinfo_get_device_id(dev_uuid, sizeof(dev_uuid));
    }

    if (err < 0) {
        dev_uuid[0] = 0xdd;
        dev_uuid[1] = 0xdd;
    }

    k_work_init(&button_work, button_pressed);

    err = board_init(&button_work);
    if (err) {
        printk("Board init failed (err: %d)\n", err);
        return;
    }

    k_work_init_delayable(&msg.work, msg_timeout);

    /* Initialize the Bluetooth Subsystem */
    err = bt_enable(bt_ready);
    if (err) {
        printk("Bluetooth init failed (err %d)\n", err);
    }

    // Set uptime
    uptime = k_uptime_get_32();
    // Initialize work queue
    // k_work_init(&send_msg_from_uart_work, send_msg_from_uart);

    // // Work queue with priority 5
    // k_work_queue_start(&send_msg_from_uart_work, work_q_stack, sizeof(work_q_stack),
    // 		   K_PRIO_COOP(5), NULL);
    // // Add work to work queue
    // k_work_submit_to_queue(&send_msg_from_uart_work, send_msg_from_uart);

    // struct k_work_q my_work_q;

    // k_work_queue_init(&my_work_q);

    // k_work_queue_start(&my_work_q, my_stack_area, K_THREAD_STACK_SIZEOF(my_stack_area),
    // 		   MY_PRIORITY, NULL);

    // struct k_work work;
    // k_work_init(&work, send_msg_from_uart);
    // k_work_submit(&work);

    // k_timer_init(&timer, timer_callback, NULL);
    // k_timer_start(&timer, K_SECONDS(5), K_SECONDS(5));
}

void test_init(uint8_t sleeptime) {
    int err;
    if (IS_ENABLED(CONFIG_HWINFO)) {
        err = hwinfo_get_device_id(dev_uuid, sizeof(dev_uuid));
    }

    if (err < 0) {
        dev_uuid[0] = 0xdd;
        dev_uuid[1] = 0xdd;
    }
}
```

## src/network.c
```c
#include "network.h"
#include "printk.h"

#include <string.h>

bool samples_deserialize(const uint8_t* buf, size_t size, struct Samples* out_samples) {
    if (size < SAMPLES_SERIALIZE_BUFFER_SIZE) {
        printk("samples_deserialize: buffer too small to hold samples\r\n");
        return false;
    }
    memcpy(out_samples, buf, sizeof(struct Samples));
    return true;
}

bool samples_serialize(uint8_t* buf, size_t size, const struct Samples* out_samples) {
    if (size < SAMPLES_SERIALIZE_BUFFER_SIZE) {
        printk("samples_serialize: buffer too small to hold samples\r\n");
        return false;
    }
    memcpy(buf, out_samples, sizeof(struct Samples));
    return true;
}

// Simple ring-buffer implementation of a queue.
static struct Samples samples_send_q[SAMPLES_TO_SEND_QUEUE_LEN];
// must be locked before every access
static struct k_mutex samples_send_q_mtx;
// read&write pointers
static size_t samples_send_q_rp = 0;
static size_t samples_send_q_wp = 0;

bool enqueue_samples_to_send(const struct Samples* samples) {
    bool result = true;
    k_mutex_lock(&samples_send_q_mtx, K_FOREVER);

    {
        if ((samples_send_q_wp + 1) % sizeof(samples_send_q) == samples_send_q_rp) {
            printk("Error: Samples-to-send queue is full\r\n");
            result = false;
            goto end;
        }
        memcpy(&samples_send_q[samples_send_q_wp], samples, sizeof(struct Samples));
        samples_send_q_wp = (samples_send_q_wp + 1) % sizeof(samples_send_q);
    }

end:
    k_mutex_unlock(&samples_send_q_mtx);
    return result;
}

bool dequeue_samples_to_send(struct Samples* out_samples) {
    bool result = true;
    k_mutex_lock(&samples_send_q_mtx, K_FOREVER);

    {
        if (samples_send_q_rp == samples_send_q_wp) {
            result = false;
            goto end;
        }
        memcpy(out_samples, &samples_send_q[samples_send_q_rp], sizeof(struct Samples));
        samples_send_q_rp = (samples_send_q_rp + 1) % sizeof(samples_send_q);
    }

end:
    k_mutex_unlock(&samples_send_q_mtx);
    return result;
}
```

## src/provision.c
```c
#include "provision.h"
#include "custom_assert.h"

#include <zephyr/drivers/hwinfo.h>

static const uint16_t net_idx;
static const uint16_t app_idx;
static uint16_t self_addr = 1, node_addr;
static uint8_t dev_uuid[16];
static uint8_t node_uuid[16];

void dev_uuid_init() {
    int err = 0;
    if (IS_ENABLED(CONFIG_HWINFO)) {
        err = hwinfo_get_device_id(dev_uuid, sizeof(dev_uuid));
    }

    if (err < 0) {
        printk("Couldn't get hardware device id, defaulting to 0xdddd\n");
        dev_uuid[0] = 0xdd;
        dev_uuid[1] = 0xdd;
    }
}

K_SEM_DEFINE(sem_unprov_beacon, 0, 1);
K_SEM_DEFINE(sem_node_added, 0, 1);
#if DT_NODE_HAS_STATUS(SW0_NODE, okay)
K_SEM_DEFINE(sem_button_pressed, 0, 1);
#endif

static struct bt_mesh_cfg_cli cfg_cli = {};

static struct bt_mesh_health_cli health_cli = {
    .current_status = health_current_status,
};

static struct bt_mesh_model root_models[] = {
    BT_MESH_MODEL_CFG_SRV,
    BT_MESH_MODEL_CFG_CLI(&cfg_cli),
    BT_MESH_MODEL_HEALTH_CLI(&health_cli),
};

static struct bt_mesh_elem elements[] = {
    BT_MESH_ELEM(0, root_models, BT_MESH_MODEL_NONE),
};

static const struct bt_mesh_comp comp = {
    .cid = BT_COMP_ID_LF,
    .elem = elements,
    .elem_count = ARRAY_SIZE(elements),
};

static const struct bt_mesh_prov prov = {
    .uuid = dev_uuid,
    .unprovisioned_beacon = unprovisioned_beacon,
    .node_added = node_added,
};

static const struct gpio_dt_spec button = GPIO_DT_SPEC_GET_OR(SW0_NODE, gpios, { 0 });
static struct gpio_callback button_cb_data;

static const struct bt_mesh_comp node_comp = {
    .cid = CONFIG_BT_COMPANY_ID,
    .elem = elements,
    .elem_count = ARRAY_SIZE(elements),
};

static const struct bt_mesh_prov node_prov = {
    .uuid = dev_uuid,
};

void health_current_status(struct bt_mesh_health_cli* cli, uint16_t addr,
    uint8_t test_id, uint16_t cid, uint8_t* faults,
    size_t fault_count) {
    size_t i;
    assert_not_null(faults);

    printk("Health Current Status from 0x%04x\r\n", addr);

    if (!fault_count) {
        printk("Health Test ID 0x%02x Company ID 0x%04x: no faults\r\n",
            test_id, cid);
        return;
    }

    printk("Health Test ID 0x%02x Company ID 0x%04x Fault Count %zu:\r\n",
        test_id, cid, fault_count);

    for (i = 0; i < fault_count; i++) {
        printk("\t0x%02x\r\n", faults[i]);
    }
}

void setup_cdb(void) {
    struct bt_mesh_cdb_app_key* key;

    key = bt_mesh_cdb_app_key_alloc(net_idx, app_idx);
    if (key == NULL) {
        printk("Failed to allocate app-key 0x%04x\r\n", app_idx);
        return;
    }

    bt_rand(key->keys[0].app_key, 16);

    if (IS_ENABLED(CONFIG_BT_SETTINGS)) {
        bt_mesh_cdb_app_key_store(key);
    }
}

void configure_self(struct bt_mesh_cdb_node* self) {
    assert_not_null(self);
    struct bt_mesh_cdb_app_key* key;
    uint8_t status = 0;
    int err;
    printk("Configuring self...\r\n");

    key = bt_mesh_cdb_app_key_get(app_idx);
    if (key == NULL) {
        printk("No app-key 0x%04x\r\n", app_idx);
        return;
    }

    /* Add Application Key */
    err = bt_mesh_cfg_app_key_add(self->net_idx, self->addr, self->net_idx,
        app_idx, key->keys[0].app_key, &status);
    if (err || status) {
        printk("Failed to add app-key (err %d, status %d)\r\n", err,
            status);
        return;
    }

    err = bt_mesh_cfg_mod_app_bind(self->net_idx, self->addr, self->addr,
        app_idx, BT_MESH_MODEL_ID_HEALTH_CLI,
        &status);
    if (err || status) {
        printk("Failed to bind app-key (err %d, status %d)\r\n", err,
            status);
        return;
    }

    atomic_set_bit(self->flags, BT_MESH_CDB_NODE_CONFIGURED);

    if (IS_ENABLED(CONFIG_BT_SETTINGS)) {
        bt_mesh_cdb_node_store(self);
    }

    printk("Configuration complete\r\n");
}
void configure_node(struct bt_mesh_cdb_node* node) {
    NET_BUF_SIMPLE_DEFINE(buf, BT_MESH_RX_SDU_MAX);
    struct bt_mesh_comp_p0_elem elem;
    struct bt_mesh_cdb_app_key* key;
    struct bt_mesh_comp_p0 local_comp;
    uint8_t status = 0;
    int err = 0;
    uint16_t elem_addr = 0;

    assert_not_null(node);

    printk("Configuring node 0x%04x...\r\n", node->addr);

    key = bt_mesh_cdb_app_key_get(app_idx);
    if (key == NULL) {
        printk("No app-key 0x%04x\r\n", app_idx);
        return;
    }

    /* Add Application Key */
    err = bt_mesh_cfg_app_key_add(net_idx, node->addr, net_idx, app_idx,
        key->keys[0].app_key, &status);
    if (err || status) {
        printk("Failed to add app-key (err %d status %d)\r\n", err, status);
        return;
    }

    /* Get the node's composition data and bind all models to the appkey */
    err = bt_mesh_cfg_comp_data_get(net_idx, node->addr, 0, &status, &buf);
    if (err || status) {
        printk("Failed to get Composition data (err %d, status: %d)\r\n",
            err, status);
        return;
    }

    err = bt_mesh_comp_p0_get(&local_comp, &buf);
    if (err) {
        printk("Unable to parse composition data (err: %d)\r\n", err);
        return;
    }

    elem_addr = node->addr;
    while (bt_mesh_comp_p0_elem_pull(&local_comp, &elem)) {
        printk("Element @ 0x%04x: %u + %u models\r\n", elem_addr,
            elem.nsig, elem.nvnd);
        for (int i = 0; i < (int)elem.nsig; i++) {
            uint16_t id = bt_mesh_comp_p0_elem_mod(&elem, i);

            if (id == BT_MESH_MODEL_ID_CFG_CLI || id == BT_MESH_MODEL_ID_CFG_SRV) {
                continue;
            }
            printk("Binding AppKey to model 0x%03x:%04x\r\n",
                elem_addr, id);

            err = bt_mesh_cfg_mod_app_bind(net_idx, node->addr,
                elem_addr, app_idx, id,
                &status);
            if (err || status) {
                printk("Failed (err: %d, status: %d)\r\n", err,
                    status);
            }
        }

        for (int i = 0; i < (int)elem.nvnd; i++) {
            struct bt_mesh_mod_id_vnd id = bt_mesh_comp_p0_elem_mod_vnd(&elem, i);

            printk("Binding AppKey to model 0x%03x:%04x:%04x\r\n",
                elem_addr, id.company, id.id);

            err = bt_mesh_cfg_mod_app_bind_vnd(net_idx, node->addr,
                elem_addr, app_idx,
                id.id, id.company,
                &status);
            if (err || status) {
                printk("Failed (err: %d, status: %d)\r\n", err,
                    status);
            }
        }

        elem_addr++;
    }

    atomic_set_bit(node->flags, BT_MESH_CDB_NODE_CONFIGURED);

    if (IS_ENABLED(CONFIG_BT_SETTINGS)) {
        bt_mesh_cdb_node_store(node);
    }

    printk("Configuration complete\r\n");
}
void unprovisioned_beacon(uint8_t uuid[16],
    bt_mesh_prov_oob_info_t oob_info,
    uint32_t* uri_hash) {
    assert_not_null(uuid);
    memcpy(node_uuid, uuid, 16);
    k_sem_give(&sem_unprov_beacon);
}

void node_added(uint16_t node_net_idx, uint8_t uuid[16], uint16_t addr, uint8_t num_elem) {
    printk("Node added: net_idx=%04x, addr=%04x, num_elem=%d\r\n", node_net_idx, addr, num_elem);
    node_addr = addr;
    k_sem_give(&sem_node_added);
    printk("Sem given for node_added\r\n");
}

int bt_ready(void) {
    uint8_t net_key[16], dev_key[16];
    int err;

    err = bt_mesh_init(&prov, &comp);
    if (err) {
        printk("Initializing mesh failed (err %d)\r\n", err);
        return err;
    }

    printk("Mesh initialized\r\n");

    if (IS_ENABLED(CONFIG_BT_SETTINGS)) {
        printk("Loading stored settings\r\n");
        settings_load();
    }

    bt_rand(net_key, 16);

    err = bt_mesh_cdb_create(net_key);
    if (err == -EALREADY) {
        printk("Using stored CDB\r\n");
    } else if (err) {
        printk("Failed to create CDB (err %d)\r\n", err);
        return err;
    } else {
        printk("Created CDB\r\n");
        setup_cdb();
    }

    bt_rand(dev_key, 16);

    err = bt_mesh_provision(net_key, BT_MESH_NET_PRIMARY, 0, 0, self_addr,
        dev_key);
    if (err == -EALREADY) {
        printk("Using stored settings\r\n");
    } else if (err) {
        printk("Provisioning failed (err %d)\r\n", err);
        return err;
    } else {
        printk("Provisioning completed\r\n");
    }

    return 0;
}
uint8_t check_unconfigured(struct bt_mesh_cdb_node* node, void* data) {
    assert_not_null(node);
    if (!atomic_test_bit(node->flags, BT_MESH_CDB_NODE_CONFIGURED)) {
        printk("Node %p's flags say it's not configured\r\n", (const void*)node);
        if (node->addr == self_addr) {
            printk("Self (%p) not configured, configuring\r\n", (const void*)node);
            configure_self(node);
        } else {
            printk("Node (%p) not configured, configuring\r\n", (const void*)node);
            configure_node(node);
        }
    }

    return BT_MESH_CDB_ITER_CONTINUE;
}
void button_pressed(const struct device* dev, struct gpio_callback* cb, uint32_t pins) {
    assert_equal(k_sem_count_get(&sem_button_pressed), 0);
    k_sem_give(&sem_button_pressed);
}

// Reset the button by removing the interrupt callback and deinitializing the pin
void button_reset(void) {
    int ret;

    assert_not_null(button.port);

    gpio_remove_callback(button.port, &button_cb_data);
    ret = gpio_pin_interrupt_configure_dt(&button, GPIO_INT_DISABLE);
    if (ret != 0) {
        printk("Error %d: failed to disable interrupt on %s pin %d\r\n", ret,
            button.port->name, button.pin);
        return;
    }
    ret = gpio_pin_configure_dt(&button, GPIO_DISCONNECTED);
    if (ret != 0) {
        printk("Error %d: failed to disconnect %s pin %d\r\n", ret, button.port->name,
            button.pin);
        return;
    }
    printk("Button reset\r\n");
}

void button_init(void) {
    int ret;

    assert_not_null(button.port);

    if (!device_is_ready(button.port)) {
        printk("Error: button device %s is not ready\r\n", button.port->name);
        return;
    }
    ret = gpio_pin_configure_dt(&button, GPIO_INPUT);
    if (ret != 0) {
        printk("Error %d: failed to configure %s pin %d\r\n", ret, button.port->name,
            button.pin);
        return;
    }
    ret = gpio_pin_interrupt_configure_dt(&button, GPIO_INT_EDGE_TO_ACTIVE);
    if (ret != 0) {
        printk("Error %d: failed to configure interrupt on %s pin %d\r\n", ret,
            button.port->name, button.pin);
        return;
    }
    gpio_init_callback(&button_cb_data, button_pressed, BIT(button.pin));
    gpio_add_callback(button.port, &button_cb_data);
    printk("Buttons are ready!\r\n");
}
bool wait_for_button_press(unsigned timeout_s) {
    // Init button
    button_init();
    k_sem_reset(&sem_button_pressed);
    int err = k_sem_take(&sem_button_pressed, K_SECONDS(timeout_s));
    if (err == -EAGAIN) {
        printk("Timed out, button 1 wasn't pressed in time.\r\n");
        // Reset button
        button_reset();
        return false;
    }
    printk("Button 1 was pressed!\r\n");
    return true;
}
void provision(void) {
    char uuid_hex_str[32 + 1];
    int err;

    printk("Initializing...\r\n");

    /* Initialize the Bluetooth Subsystem */
    err = bt_enable(NULL);
    if (err) {
        printk("Bluetooth init failed (err %d)\r\n", err);
        return;
    }

    printk("Bluetooth initialized\r\n");
    bt_ready();

#if DT_NODE_HAS_STATUS(SW0_NODE, okay)
    button_init();
#endif

    while (1) {
        printk("Resetting unprov beacon semaphore\r\n");
        k_sem_reset(&sem_unprov_beacon);
        printk("Resetting node added semaphore\r\n");
        k_sem_reset(&sem_node_added);
        printk("Checking for unconfigured nodes\r\n");
        bt_mesh_cdb_node_foreach(check_unconfigured, NULL);

        printk("Waiting for unprovisioned beacon...\r\n");
        err = k_sem_take(&sem_unprov_beacon, K_SECONDS(10));
        if (err == -EAGAIN) {
            continue;
        }

        bin2hex(node_uuid, 16, uuid_hex_str, sizeof(uuid_hex_str));

        /*
        #if DT_NODE_HAS_STATUS(SW0_NODE, okay)
                k_sem_reset(&sem_button_pressed);
                printk("Device %s detected, press button 1 to provision.\r\n", uuid_hex_str);
                err = k_sem_take(&sem_button_pressed, K_SECONDS(30));
                if (err == -EAGAIN) {
                    printk("Timed out, button 1 wasn't pressed in time.\r\n");
                    continue;
                } else if (err == -EBUSY) {
                    printk("Button pressed semaphore taken without waiting\r\n");
                }
        #endif
        */

        printk("Provisioning %s\r\n", uuid_hex_str);
        err = bt_mesh_provision_adv(node_uuid, net_idx, 0, 0);
        if (err < 0) {
            printk("Provisioning failed (err %d)\r\n", err);
            continue;
        }

        printk("Waiting for node to be added...\r\n");
        err = k_sem_take(&sem_node_added, K_SECONDS(10));
        if (err == -EAGAIN) {
            printk("Timeout waiting for node to be added\r\n");
            continue;
        } else if (err == -EBUSY) {
            printk("Node adding semaphore taken without waiting\r\n");
        }

        printk("Added node 0x%04x\r\n", node_addr);
    }
}
int run_bt_node(void) {
    int err;

    err = bt_mesh_init(&node_prov, &node_comp);
    if (err) {
        printk("Initializing mesh failed (err %d)\r\n", err);
        return 1;
    }

    printk("Mesh initialized\r\n");

    if (IS_ENABLED(CONFIG_BT_SETTINGS)) {
        printk("Loading stored settings\r\n");
        settings_load();
    }

    err = bt_mesh_prov_enable(BT_MESH_PROV_GATT | BT_MESH_PROV_ADV);
    if (err) {
        printk("bt_mesh_prov_enable failed (err %d)\r\n", err);
    } else {
        printk("bt_mesh_prov_enable ok\r\n");
    }

    return 0;
}
```
